# VPAC0_IVPAC_TOP_0_CFG_SLV_CTSET2_WRAP_CFG_CTSET2_CFG register map
Vendor: Texas Instruments
Peripheral module from a debugger description file (folder J722S).
Registers are 32-bit, access per field, reset values left out (the file's numbers can be read two ways) unless marked. A register's access mark holds for its fields unless they carry their own. Offsets are as the file gives them; lines under a group give offsets from that group; [hi:lo] are bit positions; {n}, {i} and the like mark numbered series; 'fields as' and 'values as' point back to an identical list; <NAME> marks a mode.

## VPAC0_IVPAC_TOP_0_CFG_SLV_CTSET2_WRAP_CFG_CTSET2_CFG
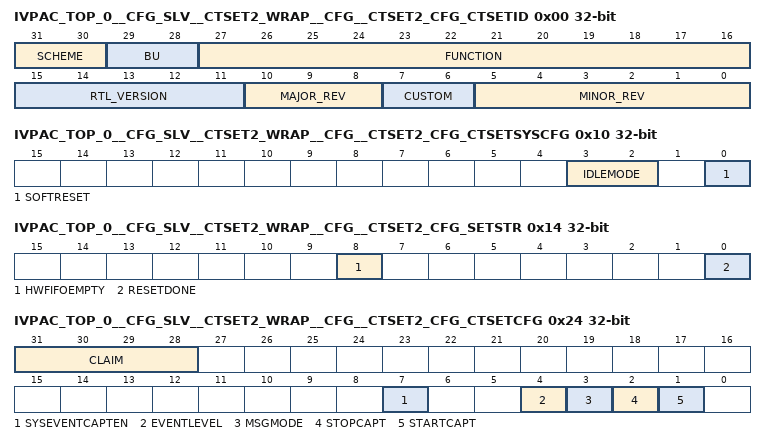
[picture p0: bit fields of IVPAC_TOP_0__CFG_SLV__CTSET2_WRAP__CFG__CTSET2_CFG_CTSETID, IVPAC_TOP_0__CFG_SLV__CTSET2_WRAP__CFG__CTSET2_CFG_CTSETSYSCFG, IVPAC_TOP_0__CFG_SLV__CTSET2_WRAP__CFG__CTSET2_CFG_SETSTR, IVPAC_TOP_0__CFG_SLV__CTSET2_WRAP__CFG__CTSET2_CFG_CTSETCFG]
0x00 IVPAC_TOP_0__CFG_SLV__CTSET2_WRAP__CFG__CTSET2_CFG_CTSETID ro — CTSET identification register
  [31:30] SCHEME — Used to distinguish between old Scheme and current
  [29:28] BU — The value 10b designates this as Processor Business Unit IP
  [27:16] FUNCTION — Function : Indicates a Debug IP (0x2nn) and 0x80 is the identifier for CT-SET
  [15:11] RTL_VERSION — This field changes on bug fix, and resets to '0' when either Minor Revision or Major Revision field changes
  [10:8] MAJOR_REV — Major Revision. This field changes when there is a major feature change.
  [7:6] CUSTOM — Indicates a special version for a particular device. 0 if non-custom
  [5:0] MINOR_REV — Minor Revision. This field changes when features are scaled up or down
0x10 IVPAC_TOP_0__CFG_SLV__CTSET2_WRAP__CFG__CTSET2_CFG_CTSETSYSCFG — CTSET system configuration register
  [3:2] IDLEMODE rw — Sets the Idle Mode for CTSET (0=Force Idle, 1=No Idle, 2=Smart Idle, 3= Smart Idle wakeup)
  [0] SOFTRESET rw — This will reset entire CTSET, except the registers and the CFG interface. This bit is automatically cleared by hardware. Reads always return 0
0x14 IVPAC_TOP_0__CFG_SLV__CTSET2_WRAP__CFG__CTSET2_CFG_SETSTR ro — CTSET status register
  [8] HWFIFOEMPTY — System Event Trace FIFO status, 1 is empty, 0 means captured data not yet exported
  [0] RESETDONE — Reset status, 0 means reset ongoing, 1 indicates completed
0x18 IVPAC_TOP_0__CFG_SLV__CTSET2_WRAP__CFG__CTSET2_CFG_DBGTIMELOW ro — The 32 low order bits of the debug time value supplied on the time input interface
  [31:0] DBGTIME — debug time
0x1C IVPAC_TOP_0__CFG_SLV__CTSET2_WRAP__CFG__CTSET2_CFG_DBGTIMEHI ro — The 32 high order bits of the debug time value supplied on the time input interface
  [31:0] DBGTIME — debug time
0x24 IVPAC_TOP_0__CFG_SLV__CTSET2_WRAP__CFG__CTSET2_CFG_CTSETCFG — The 32 low order bits of the debug time value supplied on the time input interface The 32 high order bits of the debug time value supplied on the time input interface. Reading DBGTIMEHI latches the lower 32 bits of debug time value CTSET configuration register
  [31:28] CLAIM rw — Claim control and status. To program any bits other than 31 : 28, CTSET ownership must be claimed using bits 31 : 28.
  [7] SYSEVENTCAPTEN rw — When 1 the System event capture is enabled
  [4] EVENTLEVEL rw — 0 enables low level event detection, 1 enables high level event detection
  [3] MSGMODE rw — Message generated based on event detection, 0 is sampling window, 1 is event detection
  [2] STOPCAPT rw — Stop capturing system events from external trigger detection
  [1] STARTCAPT rw — Start capturing system events from external trigger detection
0x28 IVPAC_TOP_0__CFG_SLV__CTSET2_WRAP__CFG__CTSET2_CFG_SETSPLREG — System Event Sampling Window register
  [7:0] WINDOWSIZE rw — System events sampling window size expressed as CTSET cycles
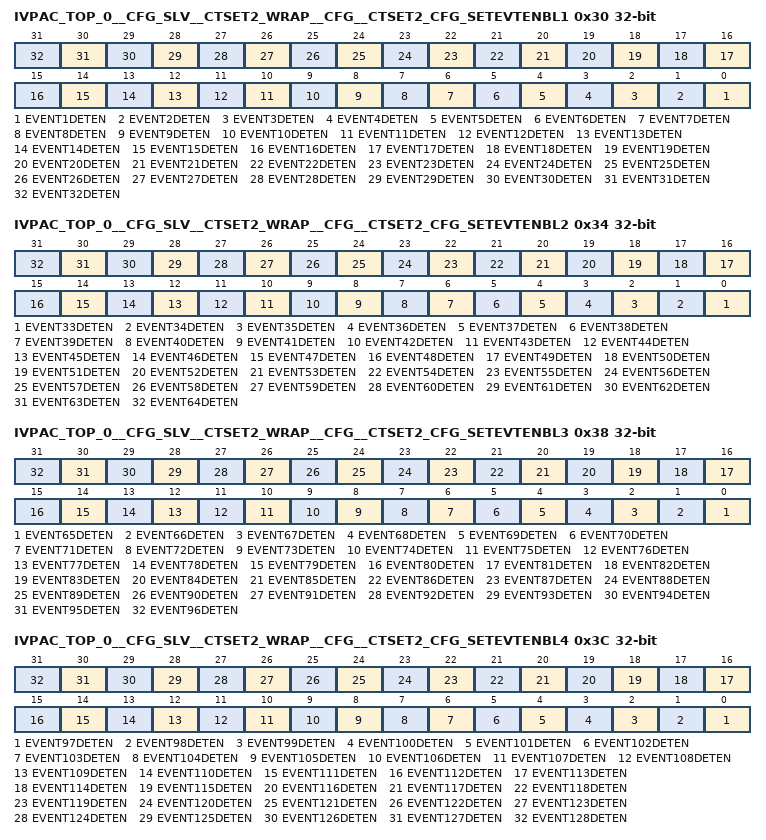
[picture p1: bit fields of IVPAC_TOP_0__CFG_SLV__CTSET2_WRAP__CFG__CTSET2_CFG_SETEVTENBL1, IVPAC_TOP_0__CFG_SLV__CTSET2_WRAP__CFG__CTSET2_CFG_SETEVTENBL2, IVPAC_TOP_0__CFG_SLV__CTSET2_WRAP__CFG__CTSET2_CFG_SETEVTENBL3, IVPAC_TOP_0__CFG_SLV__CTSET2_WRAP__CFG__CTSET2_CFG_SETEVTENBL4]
0x30 IVPAC_TOP_0__CFG_SLV__CTSET2_WRAP__CFG__CTSET2_CFG_SETEVTENBL1 rw — System event detection enable register 1
  [n-1] EVENT{n}DETEN (n=1..32) — Event({n}) Detection Enable
0x34 IVPAC_TOP_0__CFG_SLV__CTSET2_WRAP__CFG__CTSET2_CFG_SETEVTENBL2 rw — System event detection enable register 2 (if number of events > 32)
  [n-33] EVENT{n}DETEN (n=33..64) — Event({n}) Detection Enable
0x38 IVPAC_TOP_0__CFG_SLV__CTSET2_WRAP__CFG__CTSET2_CFG_SETEVTENBL3 rw — System event detection enable register 3 (if number of events > 64)
  [n-65] EVENT{n}DETEN (n=65..96) — Event({n}) Detection Enable
0x3C IVPAC_TOP_0__CFG_SLV__CTSET2_WRAP__CFG__CTSET2_CFG_SETEVTENBL4 rw — System event detection enable register 4 (if number of events > 96)
  [n-97] EVENT{n}DETEN (n=97..128) — Event({n}) Detection Enable
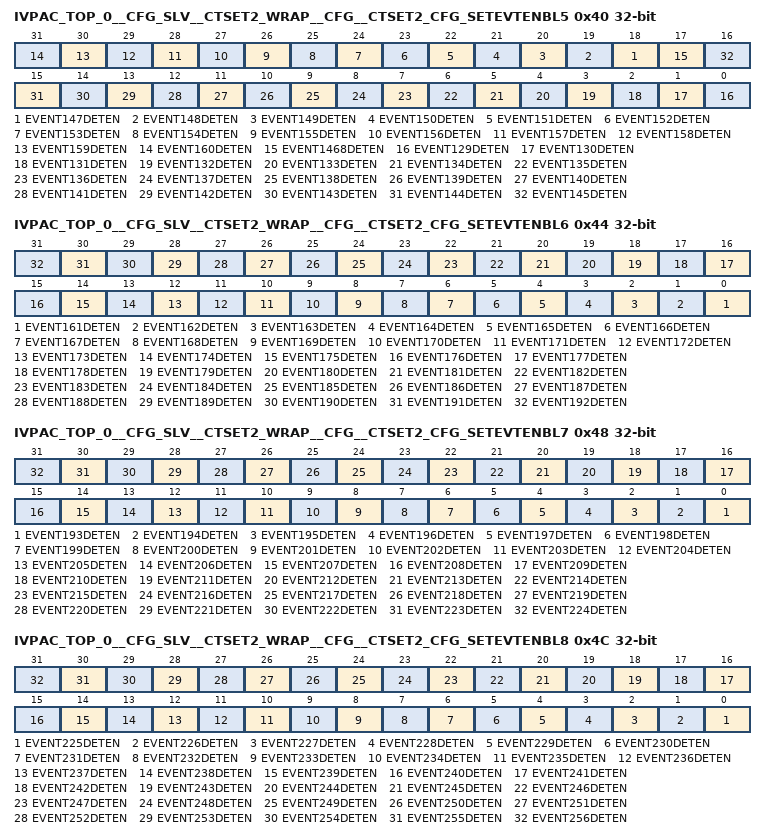
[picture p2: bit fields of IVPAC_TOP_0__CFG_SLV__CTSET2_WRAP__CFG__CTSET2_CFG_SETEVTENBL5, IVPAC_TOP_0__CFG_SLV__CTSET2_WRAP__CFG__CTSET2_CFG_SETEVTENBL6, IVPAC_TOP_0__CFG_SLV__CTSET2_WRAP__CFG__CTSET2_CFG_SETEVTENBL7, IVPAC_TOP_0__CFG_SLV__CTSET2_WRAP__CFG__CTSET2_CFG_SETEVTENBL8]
0x40 IVPAC_TOP_0__CFG_SLV__CTSET2_WRAP__CFG__CTSET2_CFG_SETEVTENBL5 rw — System event detection enable register 5 (if number of events > 128)
  [n-129] EVENT{n}DETEN (n=147..160) — Event({n}) Detection Enable
  [17] EVENT1468DETEN — Event(146) Detection Enable
  [n-129] EVENT{n}DETEN (n=129..145) — Event({n}) Detection Enable
0x44 IVPAC_TOP_0__CFG_SLV__CTSET2_WRAP__CFG__CTSET2_CFG_SETEVTENBL6 rw — System event detection enable register 6 (if number of events > 160)
  [n-161] EVENT{n}DETEN (n=161..192) — Event({n}) Detection Enable
0x48 IVPAC_TOP_0__CFG_SLV__CTSET2_WRAP__CFG__CTSET2_CFG_SETEVTENBL7 rw — System event detection enable register 7 (if number of events > 192)
  [n-193] EVENT{n}DETEN (n=193..224) — Event({n}) Detection Enable
0x4C IVPAC_TOP_0__CFG_SLV__CTSET2_WRAP__CFG__CTSET2_CFG_SETEVTENBL8 rw — System event detection enable register 8 (if number of events > 224)
  [n-225] EVENT{n}DETEN (n=225..256) — Event({n}) Detection Enable
0x50 IVPAC_TOP_0__CFG_SLV__CTSET2_WRAP__CFG__CTSET2_CFG_SETMSTID — System Event Controller ID
  [7:0] MASTID rw — HW Controller ID for System Event module. Software may overwrite the value at any time, but this is only recommended for scenarios where top-level configuration errors result in a collision between HW controller IDs
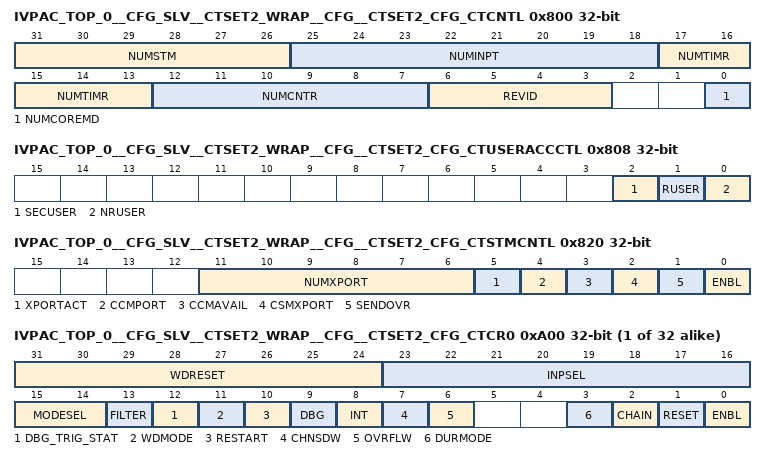
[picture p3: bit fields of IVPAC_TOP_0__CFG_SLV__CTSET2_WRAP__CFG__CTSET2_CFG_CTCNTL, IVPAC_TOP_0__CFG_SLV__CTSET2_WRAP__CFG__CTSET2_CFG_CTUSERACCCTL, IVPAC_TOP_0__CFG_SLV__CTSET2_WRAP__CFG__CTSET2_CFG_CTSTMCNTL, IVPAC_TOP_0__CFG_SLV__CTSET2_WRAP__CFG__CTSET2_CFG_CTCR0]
0x800 IVPAC_TOP_0__CFG_SLV__CTSET2_WRAP__CFG__CTSET2_CFG_CTCNTL ro — Counter Timer Control
  [31:26] NUMSTM — Number of counters that can export via STM
  [25:18] NUMINPT — Number of event input signals
  [17:13] NUMTIMR — Number of timers in the module
  [12:7] NUMCNTR — Number of counters in the module
  [6:3] REVID — Revision ID of CTSET
  [0] NUMCOREMD — Indicated the number of mode bus interfaces, 0 is 2 CPU buses, 1 is 4 buses
0x804 IVPAC_TOP_0__CFG_SLV__CTSET2_WRAP__CFG__CTSET2_CFG_CTNUMDBG ro — Counter Timer Number Debug Event Register
  [2:0] NUMEVT — Number of input selectors for debug events
0x808 IVPAC_TOP_0__CFG_SLV__CTSET2_WRAP__CFG__CTSET2_CFG_CTUSERACCCTL — Counter Timer User Access Control, can only be written in priviledged mode
  [2] SECUSER rw — Counter functions while system is in Secure-User mode
  [1] RUSER rw — Counter functions while system is in Root-User mode
  [0] NRUSER rw — Counter functions while system is in in Non-Root-User mode
0x820 IVPAC_TOP_0__CFG_SLV__CTSET2_WRAP__CFG__CTSET2_CFG_CTSTMCNTL — Counter Timer STM Control register
  [11:6] NUMXPORT ro — The total number of counters designated for export
  [5] XPORTACT ro — Indicates if a frame is currently being written to the STM.
  [4] CCMPORT rw — SW control of CCM message export
  [3] CCMAVAIL rw — CTSET supports CCM export
  [2] CSMXPORT rw — SW control of CSM message export
  [1] SENDOVR rw — Send overflow data in CSM frame
  [0] ENBL rw — CTSET STM global enable for counter/timer messages
0x824 IVPAC_TOP_0__CFG_SLV__CTSET2_WRAP__CFG__CTSET2_CFG_CTSTMMSTID — Counter Timer STM Controller ID register
  [7:0] MASTID rw — HW Controller ID for System Event module
0x828 IVPAC_TOP_0__CFG_SLV__CTSET2_WRAP__CFG__CTSET2_CFG_CTSTMINTVL — Counter Timer STM Interval Register
  [14:0] INTERVAL rw — Counter Timer Periodic export interval
0x82C IVPAC_TOP_0__CFG_SLV__CTSET2_WRAP__CFG__CTSET2_CFG_CTSTMSEL0 rw — Counter Timer STM Counter Select Register 0. This Selects Counter 0 to 31
  [31:0] COUNTSEL — The individual bit is this field indicate whether the corresponding counter value is included in the CSM message generated via the STM interface
0x830 IVPAC_TOP_0__CFG_SLV__CTSET2_WRAP__CFG__CTSET2_CFG_CTSTMSEL1 rw — Counter Timer STM Counter Select Register 1. This Selects Counter 32 to 63
  fields as IVPAC_TOP_0__CFG_SLV__CTSET2_WRAP__CFG__CTSET2_CFG_CTSTMSEL0
{0x840+4i} IVPAC_TOP_0__CFG_SLV__CTSET2_WRAP__CFG__CTSET2_CFG_CTINTVLR{i} rw (i=0..15) — These registers contain the interval match value for the corresponding timers in the CTSET. TINTVLRn are available based on number of timers instantiated.
  [31:0] INTERVAL — Interval match value for the timers in the CTSET
0x8A0 IVPAC_TOP_0__CFG_SLV__CTSET2_WRAP__CFG__CTSET2_CFG_CTDBGSGL0 — Timer Interval Register 0. Interval match value for timer 0 in CTSET Timer Interval Register 1. Interval match value for timer 1 in CTSET Timer Interval Register 2. Interval match value for timer 2 in CTSET Timer Interval Register 3. Interval match value for timer 3 in CTSET Timer Interval Register 4. Interval match value for timer 4 in CTSET Timer Interval Register 5. Interval match value for timer 5 in CTSET Timer Interval Register 6. Interval match value for timer 6 in CTSET Timer Interval Register 7. Interval match value for timer 7 in CTSET Timer Interval Register 8. Interval match value for timer 8 in CTSET Timer Interval Register 9. Interval match value for timer 9 in CTSET Timer Interval Register 10. Interval match value for timer 10 in CTSET Timer Interval Register 11. Interval match value for timer 11 in CTSET Timer Interval Register 12. Interval match value for timer 12 in CTSET Timer Interval Register 13. Interval match value for timer 13 in CTSET Timer Interval Register 14. Interval match value for timer 14 in CTSET Timer Interval Register 15. Interval match value for timer 15 in CTSET Counter Timer Debug Event Register 0
  [7:0] INPSEL rw — Counter Timer input selection
{0x8A0+4i} IVPAC_TOP_0__CFG_SLV__CTSET2_WRAP__CFG__CTSET2_CFG_CTDBGSGL{i} (i=1..4) — Counter Timer Debug Event Register {i}
  [7:0] INPSEL rw — Counter Timer input selection
0x8B4 IVPAC_TOP_0__CFG_SLV__CTSET2_WRAP__CFG__CTSET2_CFG_CTDBGSGL5 — Counter Timer Debug Event Register5
  [7:0] INPSEL rw — Counter Timer input selection
0x8B8 IVPAC_TOP_0__CFG_SLV__CTSET2_WRAP__CFG__CTSET2_CFG_CTDBGSGL6 — Counter Timer Debug Event Register 6
  [7:0] INPSEL rw — Counter Timer input selection
0x8BC IVPAC_TOP_0__CFG_SLV__CTSET2_WRAP__CFG__CTSET2_CFG_CTDBGSGL7 — Counter Timer Debug Event Register 7
  [7:0] INPSEL rw — Counter Timer input selection
0x9F0 IVPAC_TOP_0__CFG_SLV__CTSET2_WRAP__CFG__CTSET2_CFG_CTGNBL0 rw — Counter Timer Global Enable Register 0. This enables Counter 0 to 31
  [7:0] ENABLE — The individual bit is this field enables the corresponding counter. Bits 30 and 31 will be high if global time stamp output interface is enabled
0x9F4 IVPAC_TOP_0__CFG_SLV__CTSET2_WRAP__CFG__CTSET2_CFG_CTGNBL1 rw — Counter Timer Global Enable Register 1. This enables Counter 32 to 63
  [7:0] ENABLE — The individual bit is this field enables the corresponding counter
0x9F8 IVPAC_TOP_0__CFG_SLV__CTSET2_WRAP__CFG__CTSET2_CFG_CTGRST0 rw — Counter Timer Global Reset Register 0. This resets Counter 0 to 31
  [7:0] RESET — The individual bit is this field resets the corresponding counter. These bits are self-clearing, once a '1' is written, after the counters are reset these bits are cleared. When Global Time Stamp output interface is enabled, counter 31 and counter 30 should not be written to any value
0x9FC IVPAC_TOP_0__CFG_SLV__CTSET2_WRAP__CFG__CTSET2_CFG_CTGRST1 rw — Counter Timer Global Reset Register 0. This resets Counter 32 to 63
  [7:0] RESET — The individual bit is this field resets the corresponding counter. These bits are self-clearing, once a '1' is written, after the counters are reset these bits are cleared.
{0xA00+4i} IVPAC_TOP_0__CFG_SLV__CTSET2_WRAP__CFG__CTSET2_CFG_CTCR{i} (i=0..31) — Counter Timer Control Register {i}
  [31:24] WDRESET rw — WD reset event input selector. Only available for modules capable of timer and counter functions. This bit is reserved (read only) for counter registers which are only counter function
  [23:16] INPSEL rw — Counter Timer input selection. For WD mode it is the start event selector
  [15:14] MODESEL rw — Counter is in duration or occurrence mode. Only writable by debug accesses
  [13] FILTER rw — Use associated operating mode filter in CTMODEFILTERn
  [12] DBG_TRIG_STAT rw — Debug event triggered. Write 1 will clear this bit. Only available for modules capable of timer and counter functions. This bit is reserved (read only) for counter registers which are only counter function
  [11] WDMODE rw — WD Timer mode selection. Only available for modules capable of timer and counter functions. This bit is reserved (read only) for counter registers which are only counter function
  [10] RESTART rw — Restart the timer after an interval match. Only available for modules capable of timer and counter functions. This bit is reserved (read only) for counter registers which are only counter function
  [9] DBG rw — Signal debug logic on interval match. Only available for modules capable of timer and counter functions. This bit is reserved (read only) for counter registers which are only counter function
  [8] INT rw — Generate interrupt on interval match. Only available for modules capable of timer and counter functions. This bit is reserved (read only) for counter registers which are only counter function
  [7] CHNSDW rw — Counter has a shadow register for chain reads. Only valid on counters with an even number index
  [6] OVRFLW rw — Counter is in duration or occurrence mode
  [3] DURMODE rw — Counter is in duration or occurrence mode
  [2] CHAIN rw — Counter is chained to an adjacent counter
  [1] RESET rw — Counter reset control
  [0] ENBL rw — Counter enable control
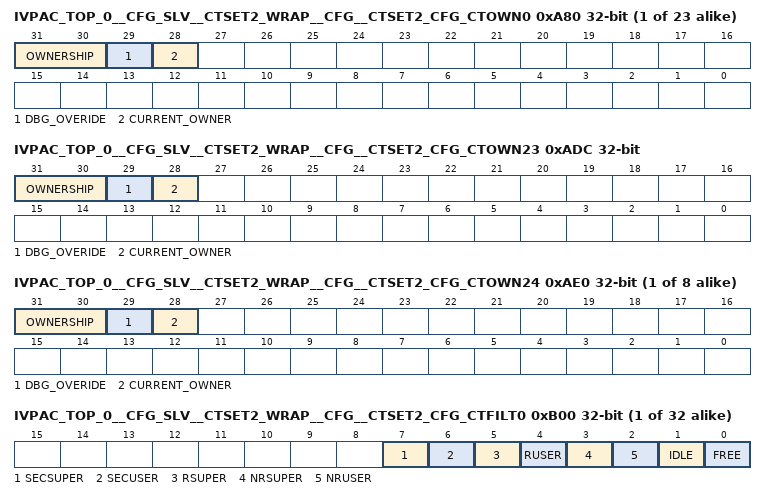
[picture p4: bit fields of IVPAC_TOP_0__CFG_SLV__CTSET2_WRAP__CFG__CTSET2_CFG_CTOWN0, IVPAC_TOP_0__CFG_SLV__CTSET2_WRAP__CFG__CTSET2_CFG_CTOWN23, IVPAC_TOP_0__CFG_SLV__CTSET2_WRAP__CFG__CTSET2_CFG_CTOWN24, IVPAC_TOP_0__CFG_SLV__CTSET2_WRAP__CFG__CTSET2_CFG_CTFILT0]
{0xA80+4i} IVPAC_TOP_0__CFG_SLV__CTSET2_WRAP__CFG__CTSET2_CFG_CTOWN{i} (i=0..22) — Counter/Timer Ownership register {i}
  [31:30] OWNERSHIP rw — Counter/Timer Ownership Status. The Read encoding is (0=Available, 1=Claimed, 2=Enabled, 3=Reserved). The write commands are (0=release, 1=claim, 2=enable, 3=nop)
  [29] DBG_OVERIDE rw — This bit indicates the debugger is Claiming the resource, always reads back as 1
  [28] CURRENT_OWNER ro — This value reflects the Counter/Timer ownership when the register is in a non-Available state, 1=Ap owned, 0=Dbg owned
0xADC IVPAC_TOP_0__CFG_SLV__CTSET2_WRAP__CFG__CTSET2_CFG_CTOWN23 — Counter/Timer Ownership register2 3
  fields as IVPAC_TOP_0__CFG_SLV__CTSET2_WRAP__CFG__CTSET2_CFG_CTOWN0
{0xA80+4i} IVPAC_TOP_0__CFG_SLV__CTSET2_WRAP__CFG__CTSET2_CFG_CTOWN{i} (i=24..31) — Counter/Timer Ownership register {i}
  fields as IVPAC_TOP_0__CFG_SLV__CTSET2_WRAP__CFG__CTSET2_CFG_CTOWN0
{0xB00+4i} IVPAC_TOP_0__CFG_SLV__CTSET2_WRAP__CFG__CTSET2_CFG_CTFILT{i} (i=0..31) — Counter Timer {i} Filter Register. These filters are only activated if the CTCRn : FILTER is set
  [7] SECSUPER rw — Counter functions while system is in Secure-Supervisor mode
  [6] SECUSER rw — Counter functions while system is in Secure-User mode
  [5] RSUPER rw — Counter functions while system is in Root-Supervisor node
  [4] RUSER rw — Counter functions while system is in Root-User mode
  [3] NRSUPER rw — Counter functions while system is in Non-Root-Supervisor mode
  [2] NRUSER rw — Counter functions while system is in in Non-Root-User mode
  [1] IDLE rw — Counter functions while system/core is in idle
  [0] FREE rw — Counter functions while system/core is halted
{0xB80+4i} IVPAC_TOP_0__CFG_SLV__CTSET2_WRAP__CFG__CTSET2_CFG_CTCNTR{i} ro (i=0..31) — Counter Timer Counter Register {i}
  [31:0] COUNT — This field reflects the current value of the counter. It is incremented when the system events configured in the corresponding Counter Control Register is asserted. If CTCRn.CHNSHD is set, the Counter will increment when the low order counter rolls over.
0xC00 IVPAC_TOP_0__CFG_SLV__CTSET2_WRAP__CFG__CTSET2_CFG_CT_EOI — Counter Timer EOI Register. This register is the End of Interrupt used by SW to signal HW that an interrupt event service is complete and an interrupt can be rearmed. This register exists only if NUMTIMR > 0
  [0] EOI rw — EOI value
0xC04 IVPAC_TOP_0__CFG_SLV__CTSET2_WRAP__CFG__CTSET2_CFG_CTIRQSTAT_RAW rw — Counter Timer IRQSTATUS RAW Register. This register indicates the raw status of the interrupt. It can be written by SW for testing. This register exists only if NUMTIMR > 0
  [31:0] TIM_INTN_IRQ — IRQSTATUS_RAW value. The individual bits is this field correspond to individual interrupts generated for each timer associated with Counter Timer Control Register (CTCRn : INT).
0xC08 IVPAC_TOP_0__CFG_SLV__CTSET2_WRAP__CFG__CTSET2_CFG_CTIRQSTAT rw — Counter Timer IRQSTATUS Register. This bit clears the interrupt event. SW can also read this bit to indicate that the interrupt is active and enabled. This register exists only if NUMTIMR > 0
  [31:0] TIM_INTN_IE — IRQSTATUS value. The individual bits is this field correspond to individual interrupts generated for each timer associated with Counter Timer Control Register (CTCRn : INT).
0xC0C IVPAC_TOP_0__CFG_SLV__CTSET2_WRAP__CFG__CTSET2_CFG_CTIRQENABLE_SET rw — Counter Timer IRQENABLE_SET Register. This register is to enable generation of Interrupt Event used by SW. This register exists only if NUMTIMR > 0
  [31:0] TIM_INTN_IES — IRQSET value. This bit sets the enable of the interrupt event. SW can also read this bit to determine if the interrupt is enabled. The individual bits is this field correspond to individual interrupts generated for each timer associated with Counter Timer Control Register (CTCRn : INT).
0xC10 IVPAC_TOP_0__CFG_SLV__CTSET2_WRAP__CFG__CTSET2_CFG_CTIRQENABLE_CLR rw — Counter Timer IRQENABLE_CLR Register. This register is to disable generation of Interrupt Event used by SW. This register exists only if NUMTIMR > 0
  [31:0] TIM_INTN_IEC — IRQCLR value. This bit clears the enable of the interrupt event. SW can also read this bit to determine if the interrupt is enabled. The individual bits is this field correspond to individual interrupts generated for each timer associated with Counter Timer Control Register (CTCRn : INT).
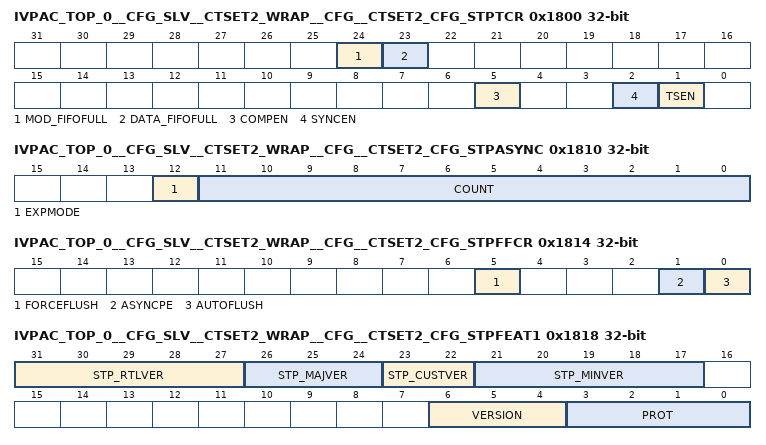
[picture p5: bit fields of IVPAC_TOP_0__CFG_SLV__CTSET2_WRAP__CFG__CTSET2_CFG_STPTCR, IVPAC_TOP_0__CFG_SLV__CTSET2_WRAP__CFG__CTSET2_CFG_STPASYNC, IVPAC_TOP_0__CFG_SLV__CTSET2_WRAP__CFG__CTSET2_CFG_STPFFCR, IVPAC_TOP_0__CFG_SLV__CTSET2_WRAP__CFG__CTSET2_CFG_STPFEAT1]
0x1800 IVPAC_TOP_0__CFG_SLV__CTSET2_WRAP__CFG__CTSET2_CFG_STPTCR — STP Trace Control Register
  [24] MOD_FIFOFULL ro — STPMI2ATB internal MID packet fifo is full
  [23] DATA_FIFOFULL ro — STPMI2ATB internal Data packet fifo is full
  [5] COMPEN rw — Compression of Data enable
  [2] SYNCEN ro — The value 1 indicates STPASYNC is supported
  [1] TSEN rw — Timestamp Enable. This bit is static and should not be changed dynamically. This should be changed before client is enabled.
0x1804 IVPAC_TOP_0__CFG_SLV__CTSET2_WRAP__CFG__CTSET2_CFG_STPTID — STP Trace ID Register
  [6:0] TRACEID rw — Trace ID value. Software may overwrite the value at any time, but this is only recommended for scenarios where top-level configuration errors result in a collision between HW controller IDs
0x1810 IVPAC_TOP_0__CFG_SLV__CTSET2_WRAP__CFG__CTSET2_CFG_STPASYNC — STP Synchronization Control Register
  [12] EXPMODE rw — Exponent mode, A value of 1 sets count to 2 to the Nth, where Nth is ((bits 11 : 8)+12). A value of 0 sets Count to N (bits 11 : 0)
  [11:0] COUNT rw — The number of bytes between Synchronization packets
0x1814 IVPAC_TOP_0__CFG_SLV__CTSET2_WRAP__CFG__CTSET2_CFG_STPFFCR — STP Flush Control Register
  [5] FORCEFLUSH rw — Write a 1 to force a flush, automatically clears after the operation is complete
  [1] ASYNCPE rw — Async Priority Enable. 0 indicates ASYNC packet priority is lower than trace. 1 indicates priority escalates on second synchronization request
  [0] AUTOFLUSH rw — Auto flush enable. When set, on every complete data (ATDATA : WIDTH) in the fifo written, data is exported out when ATREADY is asserted. This should be written before client IP enabled
0x1818 IVPAC_TOP_0__CFG_SLV__CTSET2_WRAP__CFG__CTSET2_CFG_STPFEAT1 ro — STP Features 1 Register
  [31:27] STP_RTLVER — RTL Version. Reset each time major or minor version is updated
  [26:24] STP_MAJVER — Functional Major Version. This is the first version of STPMI2ATB
  [23:22] STP_CUSTVER — Custom Version (not used)
  [21:17] STP_MINVER — Functional Minor Version
  [6:4] VERSION — STP2.0 Time Stamp, Value of 011 indicates Natural binary timestamp, a value of 100 indicates gray binary timestamps
  [3:0] PROT — Protocol Revision. Value of 0001 indicates STP 2.0
